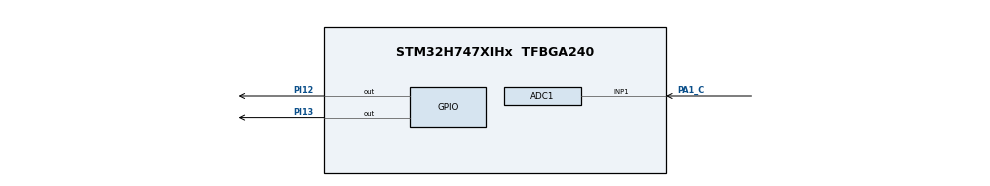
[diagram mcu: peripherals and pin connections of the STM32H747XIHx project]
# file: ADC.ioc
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Mcu.Family=STM32H7
RCC.DFSDMCLockSelection=RCC_DFSDM1CLKSOURCE_D2PCLK1
RCC.HSIDiv=RCC_PLLSAIDIVR_1
RCC.CortexFreq_Value=64000000
RCC.PLLDSIIDF=DSI_PLL_IN_DIV1
RCC.HPRE=RCC_HCLK_DIV1
Dma.ADC1.0.Polarity=HAL_DMAMUX_REQ_GEN_RISING
PA1_C.Signal=ADCx_INP1
RCC.PLLFRACN=0
RCC.PLL2FRACN=3072
RCC.RC48_VALUE=48000000
RCC.SYSCLKSource=RCC_SYSCLKSOURCE_HSI
ProjectManager.StackSize=0x400
RCC.DSIPHY_Div=8
RCC.SPI123CLockSelection=RCC_SPI123CLKSOURCE_PLL
RCC.LPUART1CLockSelection=RCC_LPUART1CLKSOURCE_D3PCLK1
RCC.I2C4CLockSelection=RCC_I2C4CLKSOURCE_D3PCLK1
RCC.RCC_MCO2Source=RCC_MCO2SOURCE_SYSCLK
RCC.ADCCLockSelection=RCC_ADCCLKSOURCE_PLL2
ADC1.Channel-3\#ChannelRegularConversion=ADC_CHANNEL_1
RCC.HCLKFreq_Value=64000000
Dma.ADC1.0.Direction=DMA_PERIPH_TO_MEMORY
PI13.Signal=GPIO_Output
Dma.ADC1.0.MemDataAlignment=DMA_MDATAALIGN_HALFWORD
RCC.HSE_VALUE=25000000
RCC.RCC_RTC_Clock_Source_FROM_HSE=RCC_RTCCLKSOURCE_HSE_DIV2
RCC.I2C123CLockSelection=RCC_I2C123CLKSOURCE_D2PCLK1
RCC.DIVM3=32
ADC1.OffsetSignedSaturation-3\#ChannelRegularConversion=DISABLE
RCC.DIVM2=4
RCC.DIVM1=5
RCC.RCC_MCO1Source=RCC_MCO1SOURCE_HSI
RCC.LPTIM2CLockSelection=RCC_LPTIM2CLKSOURCE_D3PCLK1
NVIC2.PriorityGroup=NVIC_PRIORITYGROUP_4
RCC.SAI1CLockSelection=RCC_SAI1CLKSOURCE_PLL
RCC.LPTIM345CLockSelection=RCC_LPTIM345CLKSOURCE_D3PCLK1
RCC.SPDIFCLockSelection=RCC_SPDIFRXCLKSOURCE_PLL
Dma.ADC1.0.PeriphInc=DMA_PINC_DISABLE
PI12.PinAttribute=CortexM4
RCC.RCC_MCODiv2=RCC_MCODIV_1
VP_SYS_M4_VS_Systick.Mode=SysTick
RCC.RCC_MCODiv1=RCC_MCODIV_1
CortexM7.Pins=PI13
RCC.DSI_PHY_VALUE=12288000
CortexM7.IPs=BDMA\:I,DMA\:I,FATFS_M7\:I,FREERTOS_M7\:I,IWDG1\:I,MDMA\:I,NVIC1\:I,RCC\:I,USB_DEVICE_M7\:I,USB_HOST_M7\:I,WWDG1\:I,USART1\:I,CORTEX_M7\:I,DEBUG\:I,PDM2PCM_M7\:I,PWR\:I,RESMGR_UTILITY\:I,SYS\:I,OPENAMP_M7\:I,VREFBUF\:I,ADC1\:I
RCC.CKPERSourceSelection=RCC_CLKPSOURCE_HSI
RCC.SAI23CLockSelection=RCC_SAI23CLKSOURCE_PLL
RCC.APB3Freq_Value=64000000
Mcu.Package=TFBGA240
RCC.SAI4ACLockSelection=RCC_SAI4ACLKSOURCE_PLL
RCC.PLL3FRACN=0
RCC.D1PPRE=RCC_APB3_DIV1
RCC.APB4Freq_Value=64000000
RCC.FDCANCLockSelection=RCC_FDCANCLKSOURCE_PLL
Dma.ADC1.0.FIFOMode=DMA_FIFOMODE_DISABLE
Dma.Request0=ADC1
RCC.SupplySource=PWR_DIRECT_SMPS_SUPPLY
Dma.ADC1.0.EventEnable=DISABLE
RCC.PLLDSIDev=2
RCC.DIVQ3=2
Dma.ADC1.0.Instance=DMA1_Stream0
RCC.DIVQ2=2
RCC.DIVQ1=5
RCC.D1CPRE=RCC_SYSCLK_DIV1
RCC.DSICLockSelection=RCC_DSICLKSOURCE_PHY
Dma.ADC1.0.SyncRequestNumber=1
RCC.SAI4BCLockSelection=RCC_SAI4BCLKSOURCE_PLL
RCC.DSITX_Div=4
CortexM4.Pins=PI12
RCC.DIVP3=2
ADC1.OffsetNumber-3\#ChannelRegularConversion=ADC_OFFSET_NONE
NVIC1.PriorityGroup=NVIC_PRIORITYGROUP_4
PI12.Signal=GPIO_Output
RCC.D2PPRE2=RCC_APB2_DIV1
RCC.D2PPRE1=RCC_APB1_DIV1
RCC.EXTERNAL_CLOCK_VALUE=12288000
RCC.DIVP2=2
RCC.DIVP1=2
RCC.Cortex_DivARG=SystemCoreClock/1000
RCC.PWR_Regulator_Voltage_Scale=PWR_REGULATOR_VOLTAGE_SCALE1
SH.ADCx_INP1.0=ADC1_INP1,IN1-Single-Ended
Dma.ADC1.0.PeriphDataAlignment=DMA_PDATAALIGN_HALFWORD
ProjectManager.TargetToolchain=STM32CubeIDE
PI13.PinAttribute=CortexM7
Dma.ADC1.0.Mode=DMA_NORMAL
RCC.SPI6CLockSelection=RCC_SPI6CLKSOURCE_D3PCLK1
Dma.ADC1.0.SignalID=NONE
Dma.ADC1.0.SyncSignalID=NONE
Dma.ADC1.0.Priority=DMA_PRIORITY_LOW
RCC.DIVN3=129
RCC.CECCLockSelection=RCC_CECCLKSOURCE_LSI
RCC.DIVN2=9
RCC.DIVN1=48
RCC.LPTIM1CLockSelection=RCC_LPTIM1CLKSOURCE_D2PCLK1
RCC.SWPCLockSelection=RCC_SWPMI1CLKSOURCE_D2PCLK1
RCC.USBFreq_Value=122880000
RCC.LSE_VALUE=32768
RCC.USBCLockSelection=RCC_USBCLKSOURCE_PLL
board=STM32H747I-DISCO
NVIC1.ADC_IRQn=true\:0\:0\:false\:false\:true\:true\:true
Dma.ADC1.0.SyncPolarity=HAL_DMAMUX_SYNC_NO_EVENT
RCC.APB2Freq_Value=64000000
RCC.RNGCLockSelection=RCC_RNGCLKSOURCE_HSI48
RCC.FMCCLockSelection=RCC_FMCCLKSOURCE_D1HCLK
RCC.PLLDSINDIV=20
RCC.ADCFreq_Value=75000000
RCC.PLLDSIODF=DSI_PLL_OUT_DIV1
RCC.CSI_VALUE=4000000
RCC.PLLDSIMult=2
Mcu.Name=STM32H747XIHx
RCC.SYSCLKFreq_VALUE=64000000
ADC1.master=1
RCC.Spi45ClockSelection=RCC_SPI45CLKSOURCE_D2PCLK1
ADC1.Rank-3\#ChannelRegularConversion=1
ADC1.SamplingTime-3\#ChannelRegularConversion=ADC_SAMPLETIME_1CYCLE_5
RCC.QSPICLockSelection=RCC_QSPICLKSOURCE_D1HCLK
Dma.ADC1.0.RequestNumber=1
Dma.ADC1.0.SyncEnable=DISABLE
Dma.ADC1.0.MemInc=DMA_MINC_ENABLE
ProjectManager.HeapSize=0x200
NVIC1.DMA1_Stream0_IRQn=true\:0\:0\:false\:false\:true\:false\:true
RCC.HSI_VALUE=64000000
RCC.USART234578CLockSelection=RCC_USART234578CLKSOURCE_D2PCLK1
ADC1.NbrOfConversionFlag=1
RCC.D3PPRE=RCC_APB4_DIV1
RCC.Cortex_Div=SYSTICK_CLKSOURCE_HCLK
RCC.DIVR3=2
RCC.APB1Freq_Value=64000000
RCC.DIVR2=2
RCC.DIVR1=2
PA1_C.PinAttribute=CortexM7
RCC.USART16CLockSelection=RCC_USART16CLKSOURCE_D2PCLK2
CortexM4.IPs=BDMA,DMA,FATFS_M4\:I,FREERTOS_M4\:I,IWDG2\:I,MDMA,NVIC2\:I,RCC,USB_DEVICE_M4\:I,USB_HOST_M4\:I,WWDG2\:I,USART1,USB_OTG_HS\:I,SPI2\:I,ADC3\:I,FMC\:I,QUADSPI\:I,SAI1\:I,ETH\:I,SPI5\:I,TIM8\:I,UART8\:I,DCMI\:I,RTC\:I,SDMMC1\:I,SPDIFRX1\:I,HDMI_CEC\:I,TIM13\:I,TIM3\:I,DEBUG,PDM2PCM_M4\:I,PWR,RESMGR_UTILITY,SYS_M4\:I,CORTEX_M4\:I,OPENAMP_M4\:I,VREFBUF

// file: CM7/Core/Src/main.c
/* USER CODE BEGIN Header */
/**
  ******************************************************************************
  * @file           : main.c
  * @brief          : Main program body
  ******************************************************************************
  * @attention
  *
  * <h2><center>&copy; Copyright (c) 2021 STMicroelectronics.
  * All rights reserved.</center></h2>
  *
  * This software component is licensed by ST under BSD 3-Clause license,
  * the "License"; You may not use this file except in compliance with the
  * License. You may obtain a copy of the License at:
  *                        opensource.org/licenses/BSD-3-Clause
  *
  ******************************************************************************
  */
/* USER CODE END Header */
#include "main.h"

/* USER CODE BEGIN PD */

#ifndef HSEM_ID_0
#define HSEM_ID_0 (0U) /* HW semaphore 0*/
#endif
/* USER CODE END PD */

ADC_HandleTypeDef hadc1;
DMA_HandleTypeDef hdma_adc1;

void SystemClock_Config(void);
static void MX_GPIO_Init(void);
static void MX_DMA_Init(void);
static void MX_ADC1_Init(void);

int main(void)
{
  /* USER CODE BEGIN 1 */
   int16_t value;
  /* USER CODE END 1 */
/* USER CODE BEGIN Boot_Mode_Sequence_0 */
  int32_t timeout;
/* USER CODE END Boot_Mode_Sequence_0 */

/* USER CODE BEGIN Boot_Mode_Sequence_1 */
  /* Wait until CPU2 boots and enters in stop mode or timeout*/
  timeout = 0xFFFF;
  while((__HAL_RCC_GET_FLAG(RCC_FLAG_D2CKRDY) != RESET) && (timeout-- > 0));
  if ( timeout < 0 )
  {
  Error_Handler();
  }
/* USER CODE END Boot_Mode_Sequence_1 */
  /* MCU Configuration--------------------------------------------------------*/

  /* Reset of all peripherals, Initializes the Flash interface and the Systick. */
  HAL_Init();

  /* Configure the system clock */
  SystemClock_Config();
/* USER CODE BEGIN Boot_Mode_Sequence_2 */
/* When system initialization is finished, Cortex-M7 will release Cortex-M4 by means of
HSEM notification */
/*HW semaphore Clock enable*/
__HAL_RCC_HSEM_CLK_ENABLE();
/*Take HSEM */
HAL_HSEM_FastTake(HSEM_ID_0);
/*Release HSEM in order to notify the CPU2(CM4)*/
HAL_HSEM_Release(HSEM_ID_0,0);
/* wait until CPU2 wakes up from stop mode */
timeout = 0xFFFF;
while((__HAL_RCC_GET_FLAG(RCC_FLAG_D2CKRDY) == RESET) && (timeout-- > 0));
if ( timeout < 0 )
{
Error_Handler();
}
/* USER CODE END Boot_Mode_Sequence_2 */

  /* Initialize all configured peripherals */
  MX_GPIO_Init();
  MX_DMA_Init();
  MX_ADC1_Init();

  /* Infinite loop */
  while (1)
  {

    /* USER CODE BEGIN 3 */

	  HAL_ADC_Start(&hadc1);
	  HAL_ADC_PollForConversion(&hadc1, HAL_MAX_DELAY);
	  value=HAL_ADC_GetValue(&hadc1);
	  if(value>=2000)
	  {
		  HAL_GPIO_TogglePin(GPIOI, GPIO_PIN_13);
		  HAL_Delay(500);
	  }
  }
  /* USER CODE END 3 */
}

void SystemClock_Config(void)
{
  RCC_OscInitTypeDef RCC_OscInitStruct = {0};
  RCC_ClkInitTypeDef RCC_ClkInitStruct = {0};

  /** Supply configuration update enable
  */
  HAL_PWREx_ConfigSupply(PWR_DIRECT_SMPS_SUPPLY);
  /** Configure the main internal regulator output voltage
  */
  __HAL_PWR_VOLTAGESCALING_CONFIG(PWR_REGULATOR_VOLTAGE_SCALE1);

  while(!__HAL_PWR_GET_FLAG(PWR_FLAG_VOSRDY)) {}
  /** Macro to configure the PLL clock source
  */
  __HAL_RCC_PLL_PLLSOURCE_CONFIG(RCC_PLLSOURCE_HSI);
  /** Initializes the RCC Oscillators according to the specified parameters
  * in the RCC_OscInitTypeDef structure.
  */
  RCC_OscInitStruct.OscillatorType = RCC_OSCILLATORTYPE_HSI;
  RCC_OscInitStruct.HSIState = RCC_HSI_DIV1;
  RCC_OscInitStruct.HSICalibrationValue = RCC_HSICALIBRATION_DEFAULT;
  RCC_OscInitStruct.PLL.PLLState = RCC_PLL_NONE;
  RCC_OscInitStruct.PLL.PLLSource = RCC_PLLSOURCE_HSI;
  if (HAL_RCC_OscConfig(&RCC_OscInitStruct) != HAL_OK)
  {
    Error_Handler();
  }
  /** Initializes the CPU, AHB and APB buses clocks
  */
  RCC_ClkInitStruct.ClockType = RCC_CLOCKTYPE_HCLK|RCC_CLOCKTYPE_SYSCLK
                              |RCC_CLOCKTYPE_PCLK1|RCC_CLOCKTYPE_PCLK2
                              |RCC_CLOCKTYPE_D3PCLK1|RCC_CLOCKTYPE_D1PCLK1;
  RCC_ClkInitStruct.SYSCLKSource = RCC_SYSCLKSOURCE_HSI;
  RCC_ClkInitStruct.SYSCLKDivider = RCC_SYSCLK_DIV1;
  RCC_ClkInitStruct.AHBCLKDivider = RCC_HCLK_DIV1;
  RCC_ClkInitStruct.APB3CLKDivider = RCC_APB3_DIV1;
  RCC_ClkInitStruct.APB1CLKDivider = RCC_APB1_DIV1;
  RCC_ClkInitStruct.APB2CLKDivider = RCC_APB2_DIV1;
  RCC_ClkInitStruct.APB4CLKDivider = RCC_APB4_DIV1;

  if (HAL_RCC_ClockConfig(&RCC_ClkInitStruct, FLASH_LATENCY_0) != HAL_OK)
  {
    Error_Handler();
  }
}

static void MX_ADC1_Init(void)
{

  ADC_MultiModeTypeDef multimode = {0};
  ADC_ChannelConfTypeDef sConfig = {0};

  /** Common config
  */
  hadc1.Instance = ADC1;
  hadc1.Init.ClockPrescaler = ADC_CLOCK_ASYNC_DIV4;
  hadc1.Init.Resolution = ADC_RESOLUTION_16B;
  hadc1.Init.ScanConvMode = ADC_SCAN_DISABLE;
  hadc1.Init.EOCSelection = ADC_EOC_SINGLE_CONV;
  hadc1.Init.LowPowerAutoWait = DISABLE;
  hadc1.Init.ContinuousConvMode = DISABLE;
  hadc1.Init.NbrOfConversion = 1;
  hadc1.Init.DiscontinuousConvMode = DISABLE;
  hadc1.Init.ExternalTrigConv = ADC_SOFTWARE_START;
  hadc1.Init.ExternalTrigConvEdge = ADC_EXTERNALTRIGCONVEDGE_NONE;
  hadc1.Init.ConversionDataManagement = ADC_CONVERSIONDATA_DR;
  hadc1.Init.Overrun = ADC_OVR_DATA_PRESERVED;
  hadc1.Init.LeftBitShift = ADC_LEFTBITSHIFT_NONE;
  hadc1.Init.OversamplingMode = DISABLE;
  if (HAL_ADC_Init(&hadc1) != HAL_OK)
  {
    Error_Handler();
  }
  /** Configure the ADC multi-mode
  */
  multimode.Mode = ADC_MODE_INDEPENDENT;
  if (HAL_ADCEx_MultiModeConfigChannel(&hadc1, &multimode) != HAL_OK)
  {
    Error_Handler();
  }
  /** Configure Regular Channel
  */
  sConfig.Channel = ADC_CHANNEL_1;
  sConfig.Rank = ADC_REGULAR_RANK_1;
  sConfig.SamplingTime = ADC_SAMPLETIME_1CYCLE_5;
  sConfig.SingleDiff = ADC_SINGLE_ENDED;
  sConfig.OffsetNumber = ADC_OFFSET_NONE;
  sConfig.Offset = 0;
  sConfig.OffsetSignedSaturation = DISABLE;
  if (HAL_ADC_ConfigChannel(&hadc1, &sConfig) != HAL_OK)
  {
    Error_Handler();
  }

}

static void MX_DMA_Init(void)
{

  /* DMA controller clock enable */
  __HAL_RCC_DMA1_CLK_ENABLE();

  /* DMA interrupt init */
  /* DMA1_Stream0_IRQn interrupt configuration */
  HAL_NVIC_SetPriority(DMA1_Stream0_IRQn, 0, 0);
  HAL_NVIC_EnableIRQ(DMA1_Stream0_IRQn);

}

static void MX_GPIO_Init(void)
{
  GPIO_InitTypeDef GPIO_InitStruct = {0};

  /* GPIO Ports Clock Enable */
  __HAL_RCC_GPIOI_CLK_ENABLE();
  __HAL_RCC_GPIOA_CLK_ENABLE();

  /*Configure GPIO pin Output Level */
  HAL_GPIO_WritePin(GPIOI, GPIO_PIN_13, GPIO_PIN_RESET);

  /*Configure GPIO pin : PI13 */
  GPIO_InitStruct.Pin = GPIO_PIN_13;
  GPIO_InitStruct.Mode = GPIO_MODE_OUTPUT_PP;
  GPIO_InitStruct.Pull = GPIO_NOPULL;
  GPIO_InitStruct.Speed = GPIO_SPEED_FREQ_LOW;
  HAL_GPIO_Init(GPIOI, &GPIO_InitStruct);

}

void Error_Handler(void)
{
  __disable_irq();
  while (1)
  {
  }
}

/************************ (C) COPYRIGHT STMicroelectronics *****END OF FILE****/
